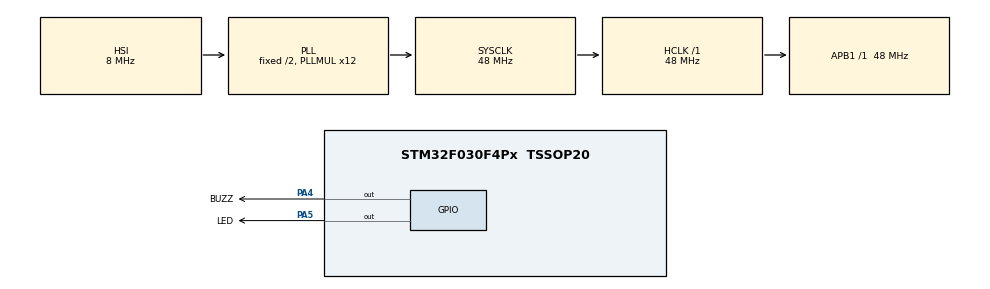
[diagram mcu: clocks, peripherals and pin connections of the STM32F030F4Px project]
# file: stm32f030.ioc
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Mcu.Family=STM32F0
Mcu.Name=STM32F030F4Px
Mcu.Package=TSSOP20
NVIC.TIM14_IRQn=true\:0\:0\:false\:false\:true\:true\:true
NVIC.TIM16_IRQn=true\:0\:0\:false\:false\:true\:true\:true
PA13.Mode=Serial_Wire
PA13.Signal=SYS_SWDIO
PA14.Mode=Serial_Wire
PA14.Signal=SYS_SWCLK
PA4.GPIO_Label=BUZZ
PA4.Signal=GPIO_Output
PA5.GPIO_Label=LED
PA5.Signal=GPIO_Output
ProjectManager.HeapSize=0x200
ProjectManager.StackSize=0x400
ProjectManager.TargetToolchain=STM32CubeIDE
RCC.AHBFreq_Value=48000000
RCC.APB1Freq_Value=48000000
RCC.APB1TimFreq_Value=48000000
RCC.HCLKFreq_Value=48000000
RCC.PLLMUL=RCC_PLL_MUL12
RCC.SYSCLKFreq_VALUE=48000000
RCC.SYSCLKSource=RCC_SYSCLKSOURCE_PLLCLK
TIM14.Period=10000-1
TIM14.Prescaler=4800-1
TIM16.AutoReloadPreload=TIM_AUTORELOAD_PRELOAD_DISABLE
TIM16.Period=100-1
TIM16.Prescaler=120-1
VP_TIM14_VS_ClockSourceINT.Mode=Enable_Timer
VP_TIM16_VS_ClockSourceINT.Mode=Enable_Timer
board=custom

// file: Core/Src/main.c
/* USER CODE BEGIN Header */
/**
  ******************************************************************************
  * @file           : main.c
  * @brief          : Main program body
  ******************************************************************************
  * @attention
  *
  * <h2><center>&copy; Copyright (c) 2020 STMicroelectronics.
  * All rights reserved.</center></h2>
  *
  * This software component is licensed by ST under BSD 3-Clause license,
  * the "License"; You may not use this file except in compliance with the
  * License. You may obtain a copy of the License at:
  *                        opensource.org/licenses/BSD-3-Clause
  *
  ******************************************************************************
  */
/* USER CODE END Header */

#include "main.h"

TIM_HandleTypeDef htim14;
TIM_HandleTypeDef htim16;

void SystemClock_Config(void);
static void MX_GPIO_Init(void);
static void MX_TIM14_Init(void);
static void MX_TIM16_Init(void);

int main(void)
{

  /* MCU Configuration--------------------------------------------------------*/

  /* Reset of all peripherals, Initializes the Flash interface and the Systick. */
  HAL_Init();

  /* Configure the system clock */
  SystemClock_Config();

  /* Initialize all configured peripherals */
  MX_GPIO_Init();
  MX_TIM14_Init();
  MX_TIM16_Init();
  /* USER CODE BEGIN 2 */
  if (HAL_TIM_Base_Start_IT(&htim14) != HAL_OK)
  {
    /* Starting Error */
    Error_Handler();
  }

  if (HAL_TIM_Base_Start_IT(&htim16) != HAL_OK)
  {
    /* Starting Error */
    Error_Handler();
  }

  /* USER CODE END 2 */

  /* Infinite loop */
  /* USER CODE BEGIN WHILE */
  while (1)
  {
	  uint16_t	arr_val;
	  arr_val = __HAL_TIM_GET_AUTORELOAD(&htim16);
	  __NOP();
	  __NOP();
	/* USER CODE END WHILE */

  }
}

void SystemClock_Config(void)
{
  RCC_OscInitTypeDef RCC_OscInitStruct = {0};
  RCC_ClkInitTypeDef RCC_ClkInitStruct = {0};

  /** Initializes the CPU, AHB and APB busses clocks
  */
  RCC_OscInitStruct.OscillatorType = RCC_OSCILLATORTYPE_HSI;
  RCC_OscInitStruct.HSIState = RCC_HSI_ON;
  RCC_OscInitStruct.HSICalibrationValue = RCC_HSICALIBRATION_DEFAULT;
  RCC_OscInitStruct.PLL.PLLState = RCC_PLL_ON;
  RCC_OscInitStruct.PLL.PLLSource = RCC_PLLSOURCE_HSI;
  RCC_OscInitStruct.PLL.PLLMUL = RCC_PLL_MUL12;
  RCC_OscInitStruct.PLL.PREDIV = RCC_PREDIV_DIV1;
  if (HAL_RCC_OscConfig(&RCC_OscInitStruct) != HAL_OK)
  {
    Error_Handler();
  }
  /** Initializes the CPU, AHB and APB busses clocks
  */
  RCC_ClkInitStruct.ClockType = RCC_CLOCKTYPE_HCLK|RCC_CLOCKTYPE_SYSCLK
                              |RCC_CLOCKTYPE_PCLK1;
  RCC_ClkInitStruct.SYSCLKSource = RCC_SYSCLKSOURCE_PLLCLK;
  RCC_ClkInitStruct.AHBCLKDivider = RCC_SYSCLK_DIV1;
  RCC_ClkInitStruct.APB1CLKDivider = RCC_HCLK_DIV1;

  if (HAL_RCC_ClockConfig(&RCC_ClkInitStruct, FLASH_LATENCY_1) != HAL_OK)
  {
    Error_Handler();
  }
}

static void MX_TIM14_Init(void)
{

  htim14.Instance = TIM14;
  htim14.Init.Prescaler = 4800-1;
  htim14.Init.CounterMode = TIM_COUNTERMODE_UP;
  htim14.Init.Period = 1200-1;
  htim14.Init.ClockDivision = TIM_CLOCKDIVISION_DIV1;
  htim14.Init.AutoReloadPreload = TIM_AUTORELOAD_PRELOAD_DISABLE;
  if (HAL_TIM_Base_Init(&htim14) != HAL_OK)
  {
    Error_Handler();
  }

}

static void MX_TIM16_Init(void)
{

  htim16.Instance = TIM16;
  htim16.Init.Prescaler = 120-1;
  htim16.Init.CounterMode = TIM_COUNTERMODE_UP;
  htim16.Init.Period = hnote;
  htim16.Init.ClockDivision = TIM_CLOCKDIVISION_DIV1;
  htim16.Init.RepetitionCounter = 0;
  htim16.Init.AutoReloadPreload = TIM_AUTORELOAD_PRELOAD_ENABLE;
  if (HAL_TIM_Base_Init(&htim16) != HAL_OK)
  {
    Error_Handler();
  }

}

static void MX_GPIO_Init(void)
{
  GPIO_InitTypeDef GPIO_InitStruct = {0};

  /* GPIO Ports Clock Enable */
  __HAL_RCC_GPIOA_CLK_ENABLE();

  /*Configure GPIO pin Output Level */
  HAL_GPIO_WritePin(GPIOA, BUZZ_Pin|LED_Pin, GPIO_PIN_RESET);

  /*Configure GPIO pins : BUZZ_Pin LED_Pin */
  GPIO_InitStruct.Pin = BUZZ_Pin|LED_Pin;
  GPIO_InitStruct.Mode = GPIO_MODE_OUTPUT_PP;
  GPIO_InitStruct.Pull = GPIO_NOPULL;
  GPIO_InitStruct.Speed = GPIO_SPEED_FREQ_LOW;
  HAL_GPIO_Init(GPIOA, &GPIO_InitStruct);

}

void Error_Handler(void)
{
}

/************************ (C) COPYRIGHT STMicroelectronics *****END OF FILE****/
